VERSION ""

NS_ :

BS_:

BU_:

BO_ 255 testMessage: 8 Vector__XXX
 SG_ testTorqueLeft : 0|32@1- (1,0) [-3.4E+038|3.4E+038] "" Vector__XXX

BO_ 112 FromEmergencySystemGPS: 8 Vector__XXX
 SG_ long : 32|32@1- (1,0) [-3.4E+038|3.4E+038] "" Vector__XXX
 SG_ lat : 0|32@1- (1,0) [-3.4E+038|3.4E+038] "" Vector__XXX

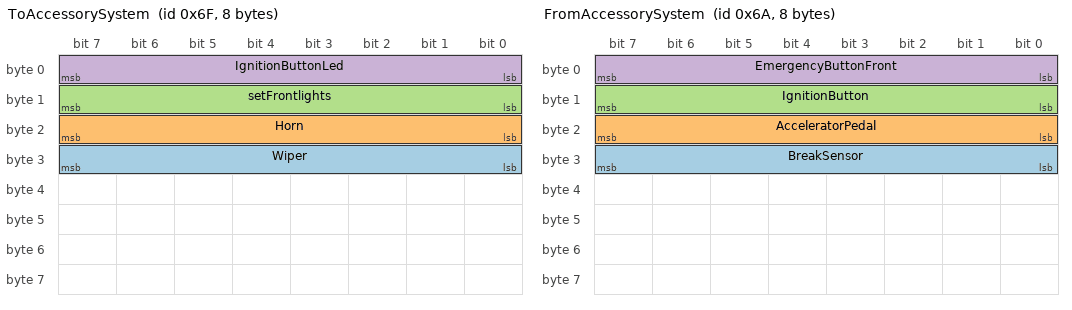
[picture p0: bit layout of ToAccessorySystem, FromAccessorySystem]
BO_ 111 ToAccessorySystem: 8 Vector__XXX
 SG_ Wiper : 24|8@1+ (1,0) [0|255] "" Vector__XXX
 SG_ Horn : 16|8@1+ (1,0) [0|255] "" Vector__XXX
 SG_ setFrontlights : 8|8@1+ (1,0) [0|255] "" Vector__XXX
 SG_ IgnitionButtonLed : 0|8@1+ (1,0) [0|255] "" Vector__XXX

BO_ 108 FromMotorControllerR: 2 Vector__XXX
 SG_ MotorControllerR_rpm : 0|16@1+ (1,0) [-32768|32767] "" Vector__XXX

BO_ 107 FromMotorControllerL: 2 Vector__XXX
 SG_ MotorControllerL_rpm : 0|16@1+ (1,0) [0|65535] "" Vector__XXX

BO_ 106 FromAccessorySystem: 8 Vector__XXX
 SG_ BreakSensor : 24|8@1+ (1,0) [0|255] "" Vector__XXX
 SG_ AcceleratorPedal : 16|8@1+ (1,0) [0|255] "" Vector__XXX
 SG_ IgnitionButton : 8|8@1+ (1,0) [0|255] "" Vector__XXX
 SG_ EmergencyButtonFront : 0|8@1+ (1,0) [0|255] "" Vector__XXX

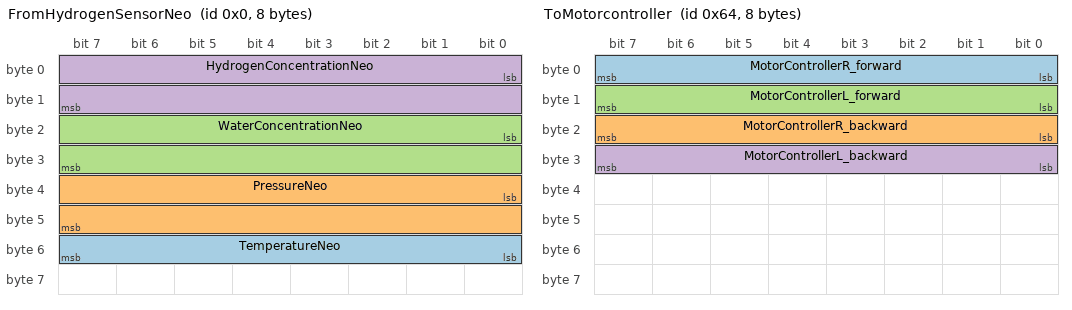
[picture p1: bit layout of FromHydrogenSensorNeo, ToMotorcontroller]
BO_ 0 FromHydrogenSensorNeo: 8 Vector__XXX
 SG_ TemperatureNeo : 48|8@1+ (1,0) [0|255] "" Vector__XXX
 SG_ PressureNeo : 32|16@1+ (1,0) [0|65535] "" Vector__XXX
 SG_ WaterConcentrationNeo : 16|16@1+ (1,0) [0|65535] "" Vector__XXX
 SG_ HydrogenConcentrationNeo : 0|16@1+ (1,0) [0|65535] "" Vector__XXX

BO_ 100 ToMotorcontroller: 8 Vector__XXX
 SG_ MotorControllerR_forward : 0|8@1+ (1,0) [0|0] "" Vector__XXX
 SG_ MotorControllerR_backward : 16|8@1+ (1,0) [0|0] "" Vector__XXX
 SG_ MotorControllerL_forward : 8|8@1+ (1,0) [0|0] "" Vector__XXX
 SG_ MotorControllerL_backward : 24|8@1+ (1,0) [0|0] "" Vector__XXX

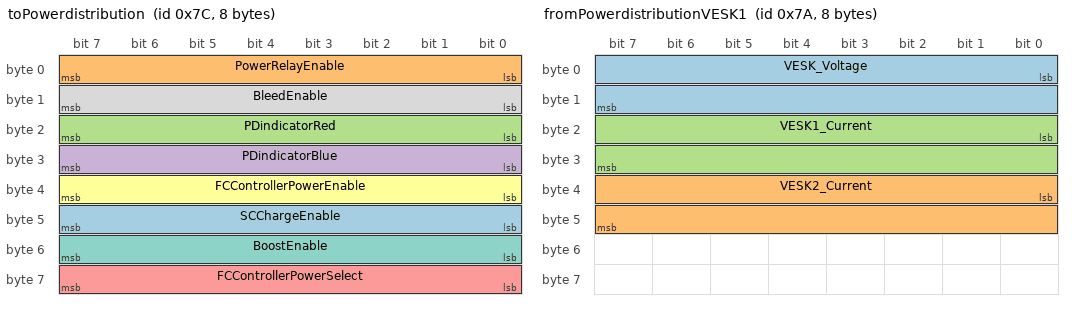
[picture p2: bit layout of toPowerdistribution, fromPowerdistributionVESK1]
BO_ 124 toPowerdistribution: 8 Vector__XXX
 SG_ SCChargeEnable : 40|8@1+ (1,0) [0|255] "" Vector__XXX
 SG_ PowerRelayEnable : 0|8@1+ (1,0) [0|255] "" Vector__XXX
 SG_ PDindicatorRed : 16|8@1+ (1,0) [0|255] "" Vector__XXX
 SG_ PDindicatorBlue : 24|8@1+ (1,0) [0|255] "" Vector__XXX
 SG_ FCControllerPowerSelect : 56|8@1+ (1,0) [0|255] "" Vector__XXX
 SG_ FCControllerPowerEnable : 32|8@1+ (1,0) [0|255] "" Vector__XXX
 SG_ BoostEnable : 48|8@1+ (1,0) [0|255] "" Vector__XXX
 SG_ BleedEnable : 8|8@1+ (1,0) [0|255] "" Vector__XXX

BO_ 123 fromPowerdistributionVESC2: 8 Vector__XXX
 SG_ VESK2_Power : 32|32@1+ (1,0) [0|0] "" Vector__XXX
 SG_ VESK1_Power : 0|32@1+ (1,0) [0|4294967295] "" Vector__XXX

BO_ 122 fromPowerdistributionVESK1: 8 Vector__XXX
 SG_ VESK_Voltage : 0|16@1+ (1,0) [0|0] "" Vector__XXX
 SG_ VESK2_Current : 32|16@1+ (1,0) [0|65535] "" Vector__XXX
 SG_ VESK1_Current : 16|16@1+ (1,0) [0|65535] "" Vector__XXX

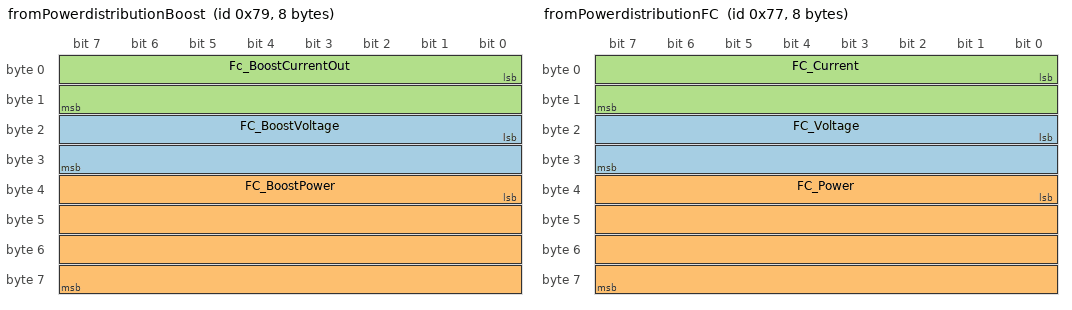
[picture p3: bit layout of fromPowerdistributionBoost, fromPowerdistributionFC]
BO_ 121 fromPowerdistributionBoost: 8 Vector__XXX
 SG_ FC_BoostVoltage : 16|16@1+ (1,0) [0|65535] "" Vector__XXX
 SG_ FC_BoostPower : 32|32@1+ (1,0) [0|4294967295] "" Vector__XXX
 SG_ Fc_BoostCurrentOut : 0|16@1+ (1,0) [0|65535] "" Vector__XXX

BO_ 120 fromPowerdistributionSC: 8 Vector__XXX
 SG_ SC_Voltage : 0|16@1+ (1,0) [0|0] "" Vector__XXX
 SG_ SC_ChargeCurrent : 16|16@1+ (1,0) [0|65535] "" Vector__XXX

BO_ 119 fromPowerdistributionFC: 8 Vector__XXX
 SG_ FC_Voltage : 16|16@1+ (1,0) [0|65535] "" Vector__XXX
 SG_ FC_Power : 32|32@1+ (1,0) [0|4294967295] "" Vector__XXX
 SG_ FC_Current : 0|16@1+ (1,0) [0|65535] "" Vector__XXX

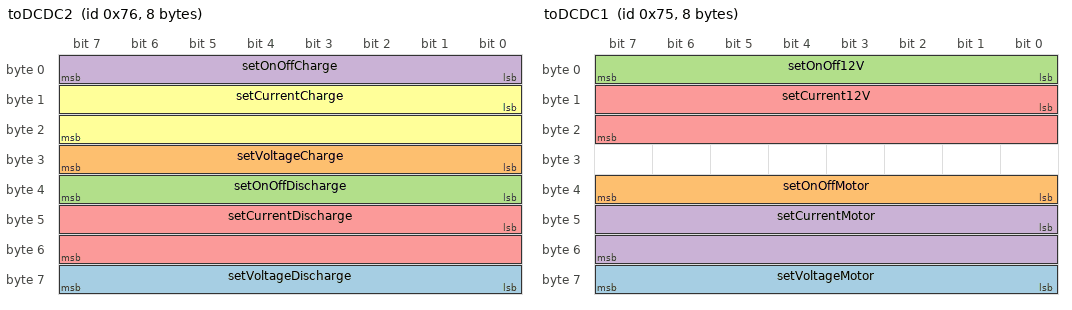
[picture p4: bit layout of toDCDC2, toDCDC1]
BO_ 118 toDCDC2: 8 Vector__XXX
 SG_ setVoltageDischarge : 56|8@1+ (1,0) [0|255] "" Vector__XXX
 SG_ setVoltageCharge : 24|8@1+ (1,0) [0|255] "" Vector__XXX
 SG_ setOnOffDischarge : 32|8@1+ (1,0) [0|255] "" Vector__XXX
 SG_ setOnOffCharge : 0|8@1+ (1,0) [0|255] "" Vector__XXX
 SG_ setCurrentDischarge : 40|16@1+ (1,0) [0|65535] "" Vector__XXX
 SG_ setCurrentCharge : 8|16@1+ (1,0) [0|65535] "" Vector__XXX

BO_ 117 toDCDC1: 8 Vector__XXX
 SG_ setVoltageMotor : 56|8@1+ (1,0) [0|255] "" Vector__XXX
 SG_ setOnOffMotor : 32|8@1+ (1,0) [0|255] "" Vector__XXX
 SG_ setOnOff12V : 0|8@1+ (1,0) [0|255] "" Vector__XXX
 SG_ setCurrentMotor : 40|16@1+ (1,0) [0|65535] "" Vector__XXX
 SG_ setCurrent12V : 8|16@1+ (1,0) [0|65535] "" Vector__XXX

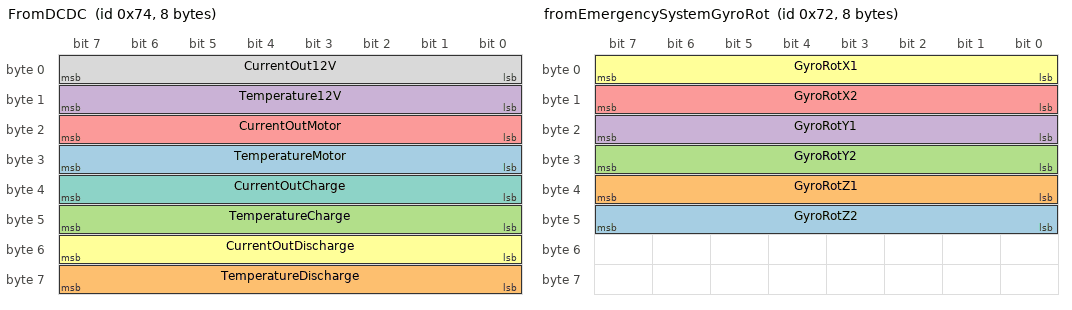
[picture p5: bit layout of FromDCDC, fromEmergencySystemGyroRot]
BO_ 116 FromDCDC: 8 Vector__XXX
 SG_ TemperatureMotor : 24|8@1+ (1,0) [0|255] "" Vector__XXX
 SG_ TemperatureDischarge : 56|8@1+ (1,0) [0|255] "" Vector__XXX
 SG_ TemperatureCharge : 40|8@1+ (1,0) [0|255] "" Vector__XXX
 SG_ Temperature12V : 8|8@1+ (1,0) [0|255] "" Vector__XXX
 SG_ CurrentOutMotor : 16|8@1+ (1,0) [0|255] "" Vector__XXX
 SG_ CurrentOutDischarge : 48|8@1+ (1,0) [0|255] "" Vector__XXX
 SG_ CurrentOutCharge : 32|8@1+ (1,0) [0|255] "" Vector__XXX
 SG_ CurrentOut12V : 0|8@1+ (1,0) [0|255] "" Vector__XXX

BO_ 115 fromSidekick: 8 Vector__XXX
 SG_ H2Massflow : 0|32@1+ (1,0) [0|4294967295] "" Vector__XXX

BO_ 114 fromEmergencySystemGyroRot: 8 Vector__XXX
 SG_ GyroRotZ2 : 40|8@1+ (1,0) [0|255] "" Vector__XXX
 SG_ GyroRotZ1 : 32|8@1+ (1,0) [0|255] "" Vector__XXX
 SG_ GyroRotY2 : 24|8@1+ (1,0) [0|255] "" Vector__XXX
 SG_ GyroRotY1 : 16|8@1+ (1,0) [0|255] "" Vector__XXX
 SG_ GyroRotX2 : 8|8@1+ (1,0) [0|255] "" Vector__XXX
 SG_ GyroRotX1 : 0|8@1+ (1,0) [0|255] "" Vector__XXX

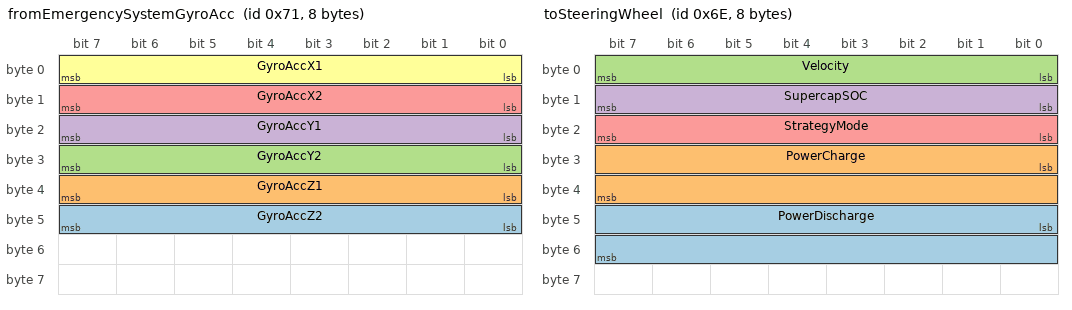
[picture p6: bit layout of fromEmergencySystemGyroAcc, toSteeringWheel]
BO_ 113 fromEmergencySystemGyroAcc: 8 Vector__XXX
 SG_ GyroAccZ2 : 40|8@1+ (1,0) [0|255] "" Vector__XXX
 SG_ GyroAccZ1 : 32|8@1+ (1,0) [0|255] "" Vector__XXX
 SG_ GyroAccY2 : 24|8@1+ (1,0) [0|255] "" Vector__XXX
 SG_ GyroAccY1 : 16|8@1+ (1,0) [0|255] "" Vector__XXX
 SG_ GyroAccX2 : 8|8@1+ (1,0) [0|255] "" Vector__XXX
 SG_ GyroAccX1 : 0|8@1+ (1,0) [0|255] "" Vector__XXX

BO_ 110 toSteeringWheel: 8 Vector__XXX
 SG_ PowerDischarge : 40|16@1+ (1,0) [0|65535] "" Vector__XXX
 SG_ PowerCharge : 24|16@1+ (1,0) [0|65535] "" Vector__XXX
 SG_ Velocity : 0|8@1+ (1,0) [0|255] "" Vector__XXX
 SG_ SupercapSOC : 8|8@1+ (1,0) [0|255] "" Vector__XXX
 SG_ StrategyMode : 16|8@1+ (1,0) [0|255] "" Vector__XXX

BO_ 109 FromSteeringWheel: 8 Vector__XXX
 SG_ SteeringWheelButtons : 0|16@1+ (1,0) [0|65535] "" Vector__XXX
 SG_ Accelerator : 16|8@1+ (1,0) [0|255] "" Vector__XXX

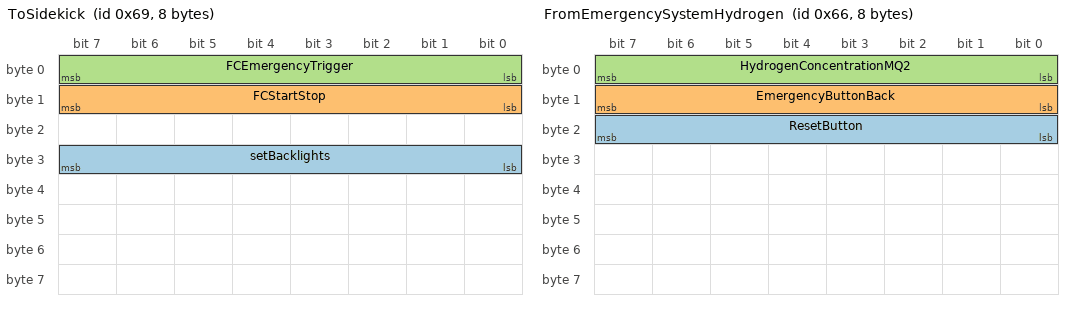
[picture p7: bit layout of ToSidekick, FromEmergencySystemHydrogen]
BO_ 105 ToSidekick: 8 Vector__XXX
 SG_ setBacklights : 24|8@1+ (1,0) [0|255] "" Vector__XXX
 SG_ FCStartStop : 8|8@1+ (1,0) [0|255] "" Vector__XXX
 SG_ FCEmergencyTrigger : 0|8@1+ (1,0) [0|255] "" Vector__XXX

BO_ 103 ToEmergencySystem: 8 Vector__XXX
 SG_ EmergencyRedLED : 0|8@1+ (1,0) [0|255] "" Vector__XXX
 SG_ EmergencyGreenLED : 8|8@1+ (1,0) [0|255] "" Vector__XXX

BO_ 102 FromEmergencySystemHydrogen: 8 Vector__XXX
 SG_ ResetButton : 16|8@1+ (1,0) [0|255] "" Vector__XXX
 SG_ EmergencyButtonBack : 8|8@1+ (1,0) [0|255] "" Vector__XXX
 SG_ HydrogenConcentrationMQ2 : 0|8@1+ (1,0) [0|255] "" Vector__XXX

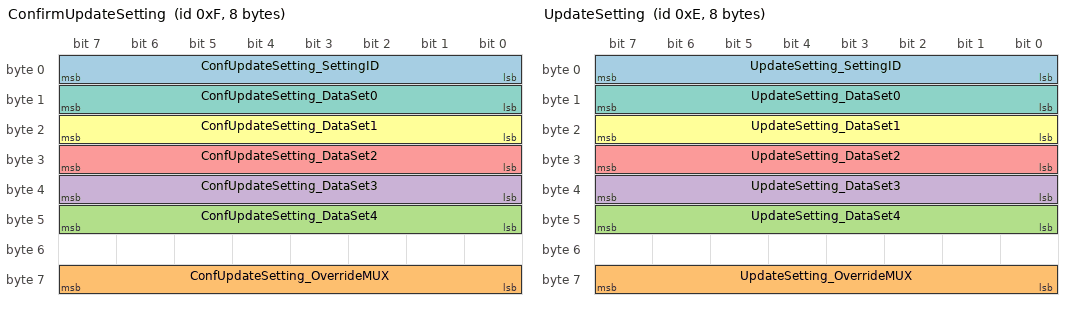
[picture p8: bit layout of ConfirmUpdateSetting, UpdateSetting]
BO_ 15 ConfirmUpdateSetting: 8 Vector__XXX
 SG_ ConfUpdateSetting_SettingID : 0|8@1+ (1,0) [0|255] "" Vector__XXX
 SG_ ConfUpdateSetting_OverrideMUX : 56|8@1+ (1,0) [0|255] "" Vector__XXX
 SG_ ConfUpdateSetting_DataSet4 : 40|8@1+ (1,0) [0|255] "" Vector__XXX
 SG_ ConfUpdateSetting_DataSet3 : 32|8@1+ (1,0) [0|255] "" Vector__XXX
 SG_ ConfUpdateSetting_DataSet2 : 24|8@1+ (1,0) [0|255] "" Vector__XXX
 SG_ ConfUpdateSetting_DataSet1 : 16|8@1+ (1,0) [0|255] "" Vector__XXX
 SG_ ConfUpdateSetting_DataSet0 : 8|8@1+ (1,0) [0|255] "" Vector__XXX

BO_ 14 UpdateSetting: 8 Vector__XXX
 SG_ UpdateSetting_SettingID : 0|8@1+ (1,0) [0|255] "" Vector__XXX
 SG_ UpdateSetting_OverrideMUX : 56|8@1+ (1,0) [0|255] "" Vector__XXX
 SG_ UpdateSetting_DataSet4 : 40|8@1+ (1,0) [0|255] "" Vector__XXX
 SG_ UpdateSetting_DataSet3 : 32|8@1+ (1,0) [0|255] "" Vector__XXX
 SG_ UpdateSetting_DataSet2 : 24|8@1+ (1,0) [0|255] "" Vector__XXX
 SG_ UpdateSetting_DataSet1 : 16|8@1+ (1,0) [0|255] "" Vector__XXX
 SG_ UpdateSetting_DataSet0 : 8|8@1+ (1,0) [0|255] "" Vector__XXX

BO_ 13 ConfirmChangeSet: 8 Vector__XXX
 SG_ ConfChangeSet_setNumber : 8|8@1+ (1,0) [0|255] "" Vector__XXX
 SG_ ConfChangeSet_ControllerID : 0|8@1+ (1,0) [0|255] "" Vector__XXX

BO_ 12 ChangeSet: 8 Vector__XXX
 SG_ ChangeSet_SetNumber : 0|8@1+ (1,0) [0|255] "" Vector__XXX

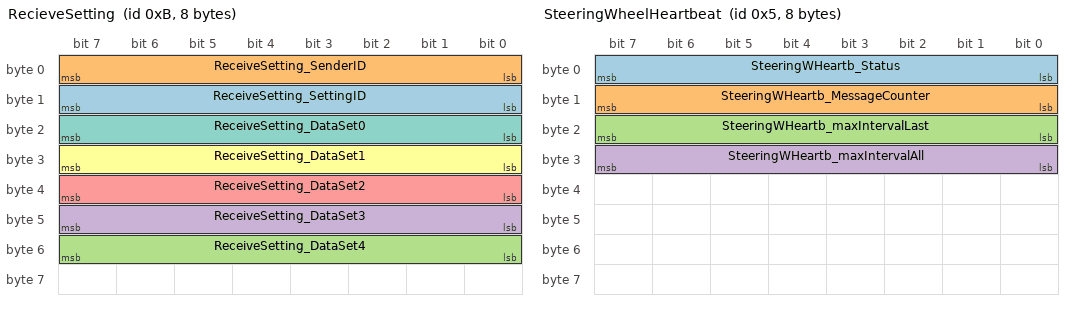
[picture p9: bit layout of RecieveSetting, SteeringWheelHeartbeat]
BO_ 11 RecieveSetting: 8 Vector__XXX
 SG_ ReceiveSetting_SettingID : 8|8@1+ (1,0) [0|255] "" Vector__XXX
 SG_ ReceiveSetting_SenderID : 0|8@1+ (1,0) [0|255] "" Vector__XXX
 SG_ ReceiveSetting_DataSet4 : 48|8@1+ (1,0) [0|255] "" Vector__XXX
 SG_ ReceiveSetting_DataSet3 : 40|8@1+ (1,0) [0|255] "" Vector__XXX
 SG_ ReceiveSetting_DataSet2 : 32|8@1+ (1,0) [0|255] "" Vector__XXX
 SG_ ReceiveSetting_DataSet1 : 24|8@1+ (1,0) [0|255] "" Vector__XXX
 SG_ ReceiveSetting_DataSet0 : 16|8@1+ (1,0) [0|255] "" Vector__XXX

BO_ 10 RequestSetting: 8 Vector__XXX
 SG_ RequestSetting_SettingID : 8|8@1+ (1,0) [0|255] "" Vector__XXX
 SG_ RequestSetting_SenderID : 0|8@1+ (1,0) [0|255] "" Vector__XXX

BO_ 5 SteeringWheelHeartbeat: 8 Vector__XXX
 SG_ SteeringWHeartb_Status : 0|8@1+ (1,0) [0|255] "" Vector__XXX
 SG_ SteeringWHeartb_MessageCounter : 8|8@1+ (1,0) [0|255] "" Vector__XXX
 SG_ SteeringWHeartb_maxIntervalLast : 16|8@1+ (1,0) [0|255] "" Vector__XXX
 SG_ SteeringWHeartb_maxIntervalAll : 24|8@1+ (1,0) [0|255] "" Vector__XXX

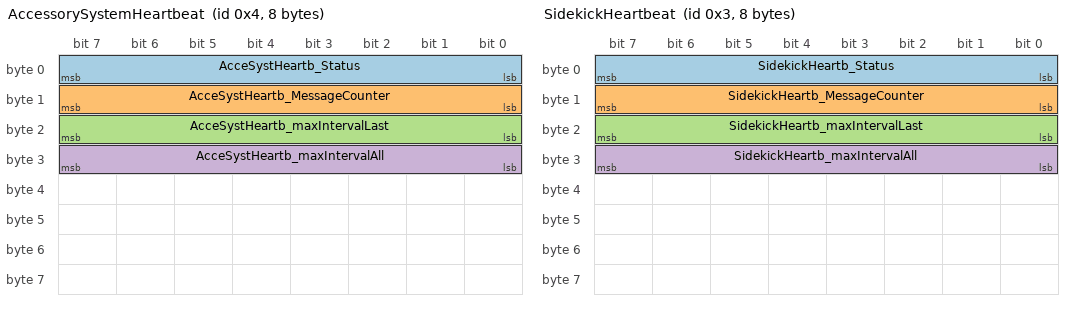
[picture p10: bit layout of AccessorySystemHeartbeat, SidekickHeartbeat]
BO_ 4 AccessorySystemHeartbeat: 8 Vector__XXX
 SG_ AcceSystHeartb_Status : 0|8@1+ (1,0) [0|255] "" Vector__XXX
 SG_ AcceSystHeartb_MessageCounter : 8|8@1+ (1,0) [0|255] "" Vector__XXX
 SG_ AcceSystHeartb_maxIntervalLast : 16|8@1+ (1,0) [0|255] "" Vector__XXX
 SG_ AcceSystHeartb_maxIntervalAll : 24|8@1+ (1,0) [0|0] "" Vector__XXX

BO_ 3 SidekickHeartbeat: 8 Vector__XXX
 SG_ SidekickHeartb_Status : 0|8@1+ (1,0) [0|255] "" Vector__XXX
 SG_ SidekickHeartb_MessageCounter : 8|8@1+ (1,0) [0|255] "" Vector__XXX
 SG_ SidekickHeartb_maxIntervalLast : 16|8@1+ (1,0) [0|255] "" Vector__XXX
 SG_ SidekickHeartb_maxIntervalAll : 24|8@1+ (1,0) [0|255] "" Vector__XXX

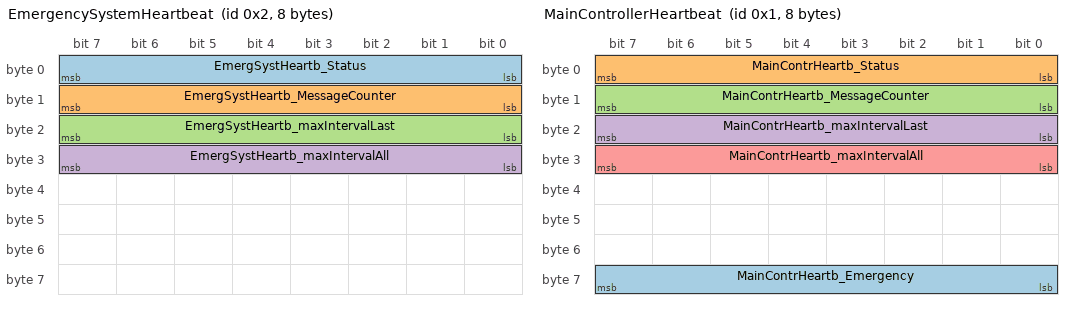
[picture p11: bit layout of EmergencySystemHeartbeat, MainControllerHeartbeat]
BO_ 2 EmergencySystemHeartbeat: 8 Vector__XXX
 SG_ EmergSystHeartb_Status : 0|8@1+ (1,0) [0|255] "" Vector__XXX
 SG_ EmergSystHeartb_MessageCounter : 8|8@1+ (1,0) [0|255] "" Vector__XXX
 SG_ EmergSystHeartb_maxIntervalLast : 16|8@1+ (1,0) [0|255] "" Vector__XXX
 SG_ EmergSystHeartb_maxIntervalAll : 24|8@1+ (1,0) [0|255] "" Vector__XXX

BO_ 1 MainControllerHeartbeat: 8 Vector__XXX
 SG_ MainContrHeartb_Emergency : 56|8@1+ (1,0) [0|255] "" Vector__XXX
 SG_ MainContrHeartb_Status : 0|8@1+ (1,0) [0|255] "" Vector__XXX
 SG_ MainContrHeartb_MessageCounter : 8|8@1+ (1,0) [0|255] "" Vector__XXX
 SG_ MainContrHeartb_maxIntervalLast : 16|8@1+ (1,0) [0|255] "" Vector__XXX
 SG_ MainContrHeartb_maxIntervalAll : 24|8@1+ (1,0) [0|255] "" Vector__XXX

BA_DEF_  "BusType" STRING ;
BA_DEF_DEF_  "BusType" "CAN";
SIG_VALTYPE_ 255 testTorqueLeft : 1;
SIG_VALTYPE_ 112 long : 1;
SIG_VALTYPE_ 112 lat : 1;
